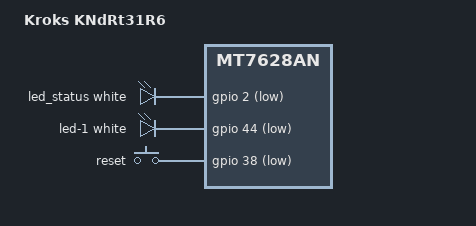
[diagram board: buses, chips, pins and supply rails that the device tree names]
#include "mt7628an_kroks.dtsi"

#include <dt-bindings/input/input.h>
#include <dt-bindings/gpio/gpio.h>
#include <dt-bindings/leds/common.h>

/ {
	compatible = "kroks,kndrt31r6", "mediatek,mt7628an-soc";
	model = "Kroks KNdRt31R6";

	aliases {
		led-boot = &led_status;
		led-failsafe = &led_status;
		led-running = &led_status;
		led-upgrade = &led_status;
	};

	gpio-leds {
		compatible = "gpio-leds";

		led_status: led-0 {
			color = <LED_COLOR_ID_WHITE>;
			gpios = <&gpio 2 GPIO_ACTIVE_LOW>;
			function = LED_FUNCTION_STATUS;
		};

		led-1 {
			color = <LED_COLOR_ID_WHITE>;
			gpios = <&gpio 44 GPIO_ACTIVE_LOW>;
			function = LED_FUNCTION_WLAN;
			linux,default-trigger = "phy0tpt";
		};
	};

	gpio-keys {
		compatible = "gpio-keys";

		reset {
			label = "reset";
			gpios = <&gpio 38 GPIO_ACTIVE_LOW>;
			linux,code = <KEY_RESTART>;
		};
	};
};

&esw {
	mediatek,portmap = <0x3e>;
	mediatek,portdisable = <0x3c>;
};

&state_default {
	gpio {
		groups = "i2s", "wdt", "wled_an";
		function = "gpio";
	};

	p0led_an {
		groups = "p0led_an";
		function = "p0led_an";
	};

	p1led_an {
		groups = "p1led_an";
		function = "p1led_an";
	};
};
